# PKA register map
Vendor: Texas Instruments
Peripheral module from a debugger description file (folder cc2538).
Registers are 32-bit, read-write, no defined reset value unless marked. A register's access mark holds for its fields unless they carry their own. Offsets are as the file gives them; lines under a group give offsets from that group; [hi:lo] are bit positions; {n}, {i} and the like mark numbered series; 'fields as' and 'values as' point back to an identical list; <NAME> marks a mode.

## PKA — Register fields should be considered static unless otherwise noted as dynamic.
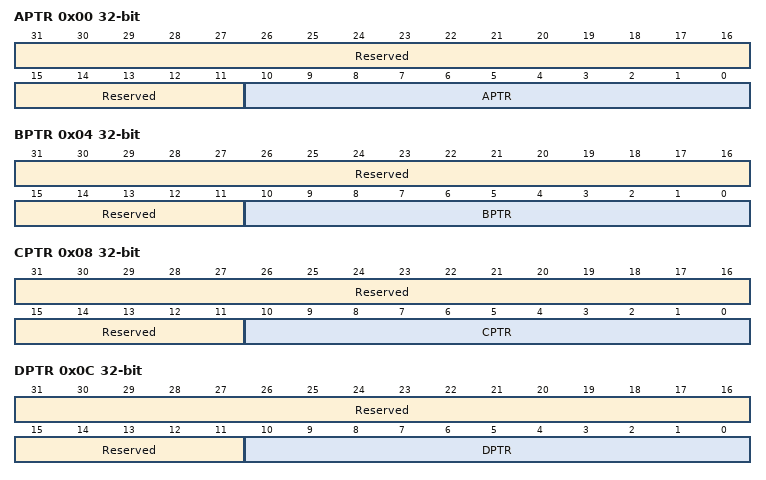
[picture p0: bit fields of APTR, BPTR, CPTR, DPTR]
0x00 APTR — PKA vector A address During execution of basic PKCP operations, this register is double buffered and can be written with a new value for the next operation; when not written, the value remains intact. During the execution of sequencer-controlled complex operations, this register may not be written and its value is undefined at the conclusion of the operation. The driver software cannot rely on the written value to remain intact.
  [31:11] Reserved — Set to zero on write, ignore on read
  [10:0] APTR — This register specifies the location of vector A within the PKA RAM. Vectors are identified through the location of their least-significant 32-bit word. Note that bit [0] must be zero to ensure that the vector starts at an 8-byte boundary.
0x04 BPTR — PKA vector B address During execution of basic PKCP operations, this register is double buffered and can be written with a new value for the next operation; when not written, the value remains intact. During the execution of sequencer-controlled complex operations, this register may not be written and its value is undefined at the conclusion of the operation. The driver software cannot rely on the written value to remain intact.
  [31:11] Reserved — Set to zero on write, ignore on read
  [10:0] BPTR — This register specifies the location of vector B within the PKA RAM. Vectors are identified through the location of their least-significant 32-bit word. Note that bit [0] must be zero to ensure that the vector starts at an 8-byte boundary.
0x08 CPTR — PKA vector C address During execution of basic PKCP operations, this register is double buffered and can be written with a new value for the next operation; when not written, the value remains intact. During the execution of sequencer-controlled complex operations, this register may not be written and its value is undefined at the conclusion of the operation. The driver software cannot rely on the written value to remain intact.
  [31:11] Reserved — Set to zero on write, ignore on read
  [10:0] CPTR — This register specifies the location of vector C within the PKA RAM. Vectors are identified through the location of their least-significant 32-bit word. Note that bit [0] must be zero to ensure that the vector starts at an 8-byte boundary.
0x0C DPTR — PKA vector D address During execution of basic PKCP operations, this register is double buffered and can be written with a new value for the next operation; when not written, the value remains intact. During the execution of sequencer-controlled complex operations, this register may not be written and its value is undefined at the conclusion of the operation. The driver software cannot rely on the written value to remain intact.
  [31:11] Reserved — Set to zero on write, ignore on read
  [10:0] DPTR — This register specifies the location of vector D within the PKA RAM. Vectors are identified through the location of their least-significant 32-bit word. Note that bit [0] must be zero to ensure that the vector starts at an 8-byte boundary.
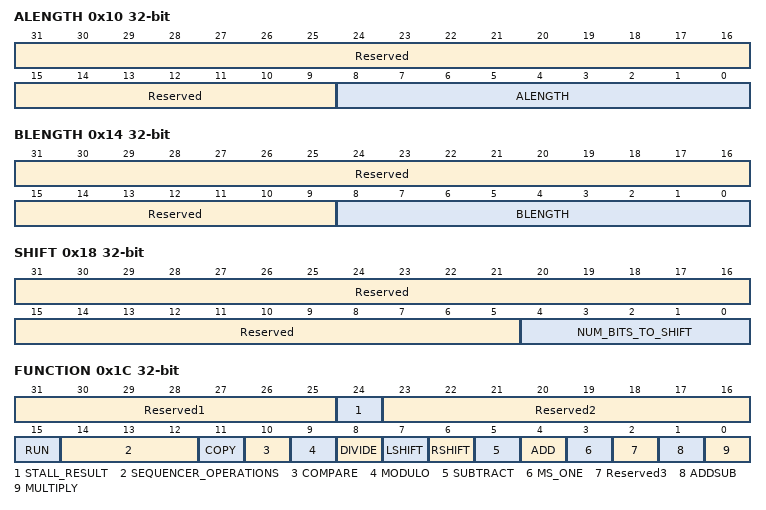
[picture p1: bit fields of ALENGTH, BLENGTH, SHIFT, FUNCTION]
0x10 ALENGTH — PKA vector A length During execution of basic PKCP operations, this register is double buffered and can be written with a new value for the next operation; when not written, the value remains intact. During the execution of sequencer-controlled complex operations, this register may not be written and its value is undefined at the conclusion of the operation. The driver software cannot rely on the written value to remain intact.
  [31:9] Reserved — Set to zero on write, ignore on read
  [8:0] ALENGTH — This register specifies the length (in 32-bit words) of Vector A.
0x14 BLENGTH — PKA vector B length During execution of basic PKCP operations, this register is double buffered and can be written with a new value for the next operation; when not written, the value remains intact. During the execution of sequencer-controlled complex operations, this register may not be written and its value is undefined at the conclusion of the operation. The driver software cannot rely on the written value to remain intact.
  [31:9] Reserved — Set to zero on write, ignore on read
  [8:0] BLENGTH — This register specifies the length (in 32-bit words) of Vector B.
0x18 SHIFT — PKA bit shift value For basic PKCP operations, modifying the contents of this register is made impossible while the operation is being performed. For the ExpMod-variable and ExpMod-CRT operations, this register is used to indicate the number of odd powers to use (directly as a value in the range 1-16). For the ModInv and ECC operations, this register is used to hold a completion code.
  [31:5] Reserved — Set to zero on write, ignore on read
  [4:0] NUM_BITS_TO_SHIFT — This register specifies the number of bits to shift the input vector (in the range 0-31) during a Rshift or Lshift operation.
0x1C FUNCTION — PKA function This register contains the control bits to start basic PKCP as well as complex sequencer operations. The run bit can be used to poll for the completion of the operation. Modifying bits [11:0] is made impossible during the execution of a basic PKCP operation. During the execution of sequencer-controlled complex operations, this register is modified; the run and stall result bits are set to zero at the conclusion, but other bits are undefined. Attention: Continuously reading this register to poll the run bit is not allowed when executing complex sequencer operations (the sequencer cannot access the PKCP when this is done). Leave at least one sysclk cycle between poll operations.
  [31:25] Reserved1 — Set to zero on write, ignore on read
  [24] STALL_RESULT — When written with a 1b, updating of the PKA_COMPARE, PKA_MSW and PKA_DIVMSW registers, as well as resetting the run bit is stalled beyond the point that a running operation is actually finished. Use this to allow software enough time to read results from a previous operation when the newly started operation is known to take only a short amount of time. If a result is waiting, the result registers is updated and the run bit is reset in the clock cycle following writing the stall result bit back to 0b. The Stall result function may only be used for basic PKCP operations.
  [23:16] Reserved2 — Set to zero on write, ignore on read
  [15] RUN — The host sets this bit to instruct the PKA module to begin processing the basic PKCP or complex sequencer operation. This bit is reset low automatically when the operation is complete. The complement of this bit is output as interrupts[1]. After a reset, the run bit is always set to 1b. Depending on the option, program ROM or program RAM, the following applies: Program ROM - The first sequencer instruction sets the bit to 0b. This is done immediately after the hardware reset is released. Program RAM - The sequencer must set the bit to 0b. As a valid firmware may not have been loaded, the sequencer is held in software reset after the hardware reset is released (the reset bit in PKA_SEQ_CRTL is set to 1b). After the FW image is loaded and the Reset bit is cleared, the sequencer starts to execute the FW. The first instruction clears the run bit. In both cases a few clock cycles are needed before the first instruction is executed and the run bit state has been propagated.
  [14:12] SEQUENCER_OPERATIONS — These bits select the complex sequencer operation to perform: 000b: None 001b: ExpMod-CRT 010b: ExpMod-ACT4 (compatible with EIP2315) 011b: ECC-ADD (if available in firmware, otherwise reserved) 100b: ExpMod-ACT2 (compatible with EIP2316) 101b: ECC-MUL (if available in firmware, otherwise reserved) 110b: ExpMod-variable 111b: ModInv (if available in firmware, otherwise reserved) The encoding of these operations is determined by sequencer firmware.
  [11] COPY — Perform copy operation
  [10] COMPARE — Perform compare operation
  [9] MODULO — Perform modulo operation
  [8] DIVIDE — Perform divide operation
  [7] LSHIFT — Perform left shift operation
  [6] RSHIFT — Perform right shift operation
  [5] SUBTRACT — Perform subtract operation
  [4] ADD — Perform add operation
  [3] MS_ONE — Loads the location of the Most Significant one bit within the result word indicated in the PKA_MSW register into bits [4:0] of the PKA_DIVMSW register - can only be used with basic PKCP operations, except for Divide, Modulo and Compare.
  [2] Reserved3 — Set to zero on write, ignore on read
  [1] ADDSUB — Perform combined add/subtract operation
  [0] MULTIPLY — Perform multiply operation
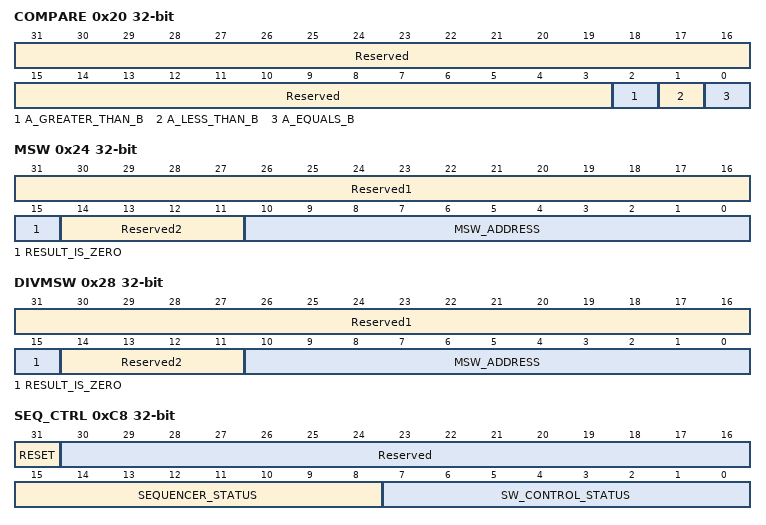
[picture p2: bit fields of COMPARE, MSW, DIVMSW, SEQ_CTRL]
0x20 COMPARE ro — PKA compare result This register provides the result of a basic PKCP compare operation. It is updated when the run bit in the PKA_FUNCTION register is reset at the end of that operation. Status after a complex sequencer operation is unknown
  [31:3] Reserved — Ignore on read
  [2] A_GREATER_THAN_B — Vector_A is greater than Vector_B
  [1] A_LESS_THAN_B — Vector_A is less than Vector_B
  [0] A_EQUALS_B — Vector_A is equal to Vector_B
0x24 MSW ro — PKA most-significant-word of result vector This register indicates the (word) address in the PKA RAM where the most significant nonzero 32-bit word of the result is stored. Should be ignored for modulo operations. For basic PKCP operations, this register is updated when the run bit in the PKA_FUNCTION register is reset at the end of the operation. For the complex-sequencer controlled operations, updating of the final value matching the actual result is done near the end of the operation; note that the result is only meaningful if no errors were detected and that for ECC operations, the PKA_MSW register will provide information for the x-coordinate of the result point only.
  [31:16] Reserved1 — Ignore on read
  [15] RESULT_IS_ZERO — The result vector is all zeroes, ignore the address returned in bits [10:0]
  [14:11] Reserved2 — Ignore on read
  [10:0] MSW_ADDRESS — Address of the most-significant nonzero 32-bit word of the result vector in PKA RAM
0x28 DIVMSW ro — PKA most-significant-word of divide remainder This register indicates the (32-bit word) address in the PKA RAM where the most significant nonzero 32-bit word of the remainder result for the basic divide and modulo operations is stored. Bits [4:0] are loaded with the bit number of the most-significant nonzero bit in the most-significant nonzero word when MS one control bit is set. For divide, modulo, and MS one reporting, this register is updated when the RUN bit in the PKA_FUNCTION register is reset at the end of the operation. For the complex sequencer controlled operations, updating of bits [4:0] of this register with the most-significant bit location of the actual result is done near the end of the operation. The result is meaningful only if no errors were detected and that for ECC operations; the PKA_DIVMSW register provides information for the x-coordinate of the result point only.
  [31:16] Reserved1 — Ignore on read
  [15] RESULT_IS_ZERO — The result vector is all zeroes, ignore the address returned in bits [10:0]
  [14:11] Reserved2 — Ignore on read
  [10:0] MSW_ADDRESS — Address of the most significant nonzero 32-bit word of the remainder result vector in PKA RAM
0xC8 SEQ_CTRL access per field — PKA sequencer control and status register The sequencer is interfaced with the outside world through a single control and status register. With the exception of bit [31], the actual use of bits in the separate sub-fields of this register is determined by the sequencer firmware. This register need only be accessed when the sequencer program is stored in RAM. The reset value of the RESTE bit depends upon the option chosen for sequencer program storage.
  [31] RESET rw — Option program ROM: Reset value = 0. Read/Write, reset value 0b (ZERO). Writing 1b resets the sequencer, write to 0b to restart operations again. As the reset value is 0b, the sequencer will automatically start operations executing from program ROM. This bit should always be written with zero and ignored when reading this register. Option Program RAM: Reset value =1. Read/Write, reset value 1b (ONE). When 1b, the sequencer is held in a reset state and the PKA_PROGRAM area is accessible for loading the sequencer program (while the PKA_DATA_RAM is inaccessible), write to 0b to (re)start sequencer operations and disable PKA_PROGRAM area accessibility (also enables the PKA_DATA_RAM accesses). Resetting the sequencer (in order to load other firmware) should only be done when the PKA Engine is not performing any operations (i.e. the run bit in the PKA_FUNCTION register should be zero).
  [30:16] Reserved rw — Set to zero on write, ignore on read
  [15:8] SEQUENCER_STATUS ro — These read-only bits can be used by the sequencer to communicate status to the outside world. Bit [8] is also used as sequencer interrupt, with the complement of this bit ORed into the run bit in PKA_FUNCTION. This field should always be written with zeroes and ignored when reading this register.
  [7:0] SW_CONTROL_STATUS rw — These bits can be used by software to trigger sequencer operations. External logic can set these bits by writing 1b, cannot reset them by writing 0b. The sequencer can reset these bits by writing 0b, cannot set them by writing 1b. Setting the run bit in PKA_FUNCTION together with a nonzero sequencer operations field automatically sets bit [0] here. This field should always be written with zeroes and ignored when reading this register.
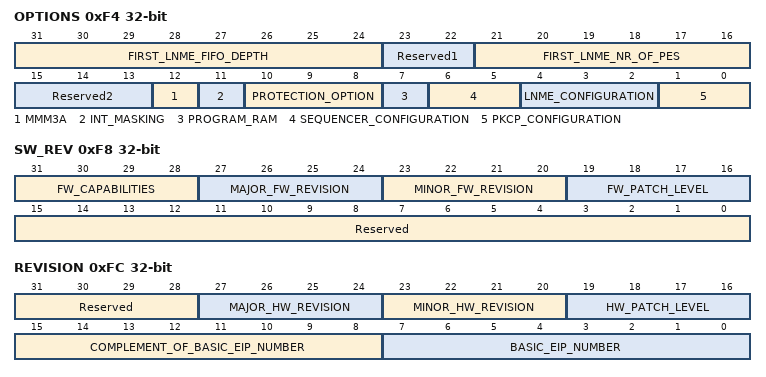
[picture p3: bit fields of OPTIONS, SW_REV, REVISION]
0xF4 OPTIONS ro — PKA hardware options register This register provides the host with a means to determine the hardware configuration implemented in this PKA engine, focused on options that have an effect on software interacting with the module. Note: (32 x (1st LNME nr. of PEs + 1st LNME FIFO RAM depth - 10)) equals the maximum modulus vector length (in bits) that can be handled by the modular exponentiation and ECC operations executed on a PKA engine that includes an LNME.
  [31:24] FIRST_LNME_FIFO_DEPTH — Number of words in the first LNME's FIFO RAM Should be ignored if LNME configuration is 0. The contents of this field indicate the actual depth as selected by the LNME FIFO RAM size strap input, fifo_size_sel. Note: Reset value is undefined
  [23:22] Reserved1 — Ignore on read
  [21:16] FIRST_LNME_NR_OF_PES — Number of processing elements in the pipeline of the first LNME Should be ignored if LNME configuration is 0. Note: Reset value is undefined.
  [15:13] Reserved2 — Ignore on read
  [12] MMM3A — Reserved for a future functional extension to the LNME Always 0b
  [11] INT_MASKING — Value 0b indicates that the main interrupt output (bit [1] of the interrupts output bus) is the direct complement of the run bit in the PKA_CONTROL register, value 1b indicates that interrupt masking logic is present for this output. Note: Reset value is undefined
  [10:8] PROTECTION_OPTION — Value 0 indicates no additional protection against side channel attacks, value 1 indicates the SCAP option, value 3 indicates the PROT option; other values are reserved. Note: Reset value is undefined
  [7] PROGRAM_RAM — Value 1b indicates sequencer program storage in RAM, value 0b in ROM. Note: Reset value is undefined
  [6:5] SEQUENCER_CONFIGURATION — Value 1 indicates a standard sequencer; other values are reserved.
  [4:2] LNME_CONFIGURATION — Value 0 indicates NO LNME, value 1 indicates one standard LNME (with alpha = 32, beta = 8); other values reserved. Note: Reset value is undefined
  [1:0] PKCP_CONFIGURATION — Value 1 indicates a PKCP with a 16x16 multiplier, value 2 indicates a PKCP with a 32x32 multiplier, other values reserved. Note: Reset value is undefined.
0xF8 SW_REV ro — PKA firmware revision and capabilities register This register allows the host access to the internal firmware revision number of the PKA Engine for software driver matching and diagnostic purposes. This register also contains a field that encodes the capabilities of the embedded firmware. The PKA_SW_REV register is written by the firmware within a few clock cycles after starting up that firmware. The hardware reset value is zero, indicating that the information has not been written yet.
  [31:28] FW_CAPABILITIES — 4-bit binary encoding for the functionality implemented in the firmware. Value 0 indicates basic ModExp with/without CRT. Value 1 adds Modular Inversion, value 2 adds Modular Inversion and ECC operations. Values 3-15 are reserved.
  [27:24] MAJOR_FW_REVISION — 4-bit binary encoding of the major firmware revision number
  [23:20] MINOR_FW_REVISION — 4-bit binary encoding of the minor firmware revision number
  [19:16] FW_PATCH_LEVEL — 4-bit binary encoding of the firmware patch level, initial release will carry value zero Patches are used to remove bugs without changing the functionality or interface of a module.
  [15:0] Reserved — Ignore on read
0xFC REVISION ro — PKA hardware revision register This register allows the host access to the hardware revision number of the PKA engine for software driver matching and diagnostic purposes. It is always located at the highest address in the access space of the module and contains an encoding of the EIP number (with its complement as signature) for recognition of the hardware module.
  [31:28] Reserved — Ignore on read
  [27:24] MAJOR_HW_REVISION — 4-bit binary encoding of the major hardware revision number
  [23:20] MINOR_HW_REVISION — 4-bit binary encoding of the minor hardware revision number
  [19:16] HW_PATCH_LEVEL — 4-bit binary encoding of the hardware patch level, initial release will carry value zero Patches are used to remove bugs without changing the functionality or interface of a module.
  [15:8] COMPLEMENT_OF_BASIC_EIP_NUMBER — Bit-by-bit logic complement of bits [7:0], EIP-28 gives 0xE3
  [7:0] BASIC_EIP_NUMBER — 8-bit binary encoding of the EIP number, EIP-28 gives 0x1C
